VERSION ""

NS_ :

BS_:

BU_: Pegasus Marvel Laptop Stark Xavier stark NBMS Pegasus Marvel Laptop Stark Xavier stark Gtake

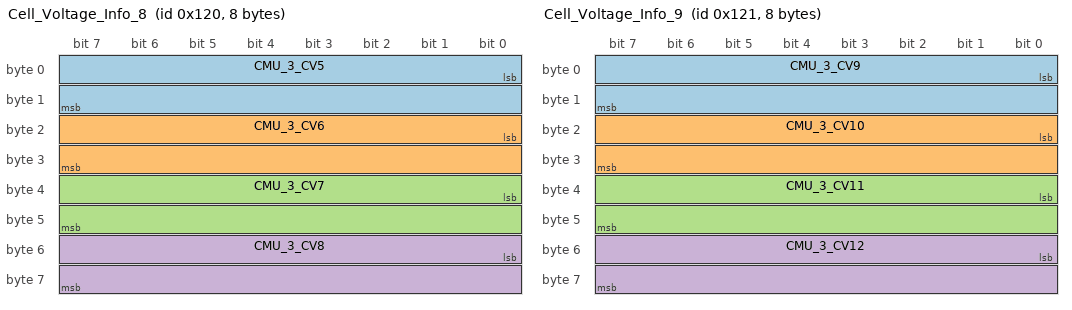
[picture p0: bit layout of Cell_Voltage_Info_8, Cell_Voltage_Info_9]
BO_ 288 Cell_Voltage_Info_8: 8 NBMS
 SG_ CMU_3_CV5 : 0|16@1+ (0.1,0) [0|6553.5] "mV" Vector__XXX
 SG_ CMU_3_CV6 : 16|16@1+ (0.1,0) [0|6553.5] "mV" Vector__XXX
 SG_ CMU_3_CV7 : 32|16@1+ (0.1,0) [0|6553.5] "mV" Vector__XXX
 SG_ CMU_3_CV8 : 48|16@1+ (0.1,0) [0|6553.5] "mV" Vector__XXX

BO_ 298 Battery_Parameters_4: 8 NBMS
 SG_ DCLI : 0|16@1+ (0.1,0) [0|6553.5] "A" Vector__XXX
 SG_ DCLO : 16|16@1+ (0.1,0) [0|6553.5] "A" Vector__XXX

BO_ 289 Cell_Voltage_Info_9: 8 NBMS
 SG_ CMU_3_CV9 : 0|16@1+ (0.1,0) [0|6553.5] "mV" Vector__XXX
 SG_ CMU_3_CV10 : 16|16@1+ (0.1,0) [0|6553.5] "mV" Vector__XXX
 SG_ CMU_3_CV11 : 32|16@1+ (0.1,0) [0|6553.5] "mV" Vector__XXX
 SG_ CMU_3_CV12 : 48|16@1+ (0.1,0) [0|6553.5] "mV" Vector__XXX

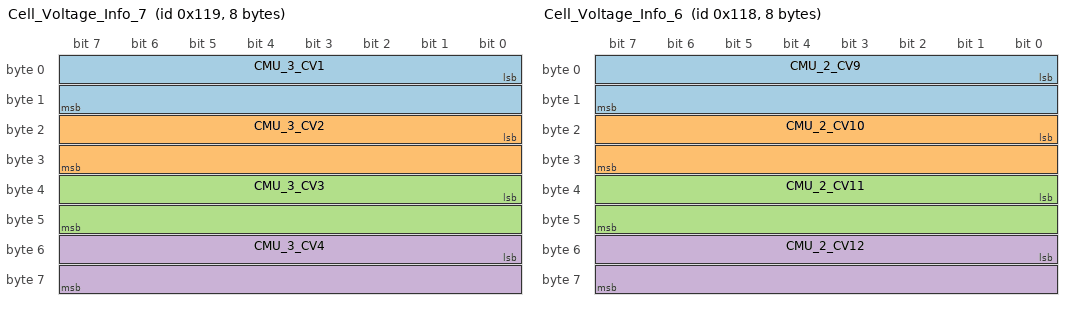
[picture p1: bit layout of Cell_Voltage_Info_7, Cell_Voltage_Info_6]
BO_ 281 Cell_Voltage_Info_7: 8 NBMS
 SG_ CMU_3_CV1 : 0|16@1+ (0.1,0) [0|6553.5] "mV" Vector__XXX
 SG_ CMU_3_CV2 : 16|16@1+ (0.1,0) [0|6553.5] "mV" Vector__XXX
 SG_ CMU_3_CV3 : 32|16@1+ (0.1,0) [0|6553.5] "mV" Vector__XXX
 SG_ CMU_3_CV4 : 48|16@1+ (0.1,0) [0|6553.5] "mV" Vector__XXX

BO_ 280 Cell_Voltage_Info_6: 8 NBMS
 SG_ CMU_2_CV9 : 0|16@1+ (0.1,0) [0|6553.5] "mV" Vector__XXX
 SG_ CMU_2_CV10 : 16|16@1+ (0.1,0) [0|6553.5] "mV" Vector__XXX
 SG_ CMU_2_CV11 : 32|16@1+ (0.1,0) [0|6553.5] "mV" Vector__XXX
 SG_ CMU_2_CV12 : 48|16@1+ (0.1,0) [0|6553.5] "mV" Vector__XXX

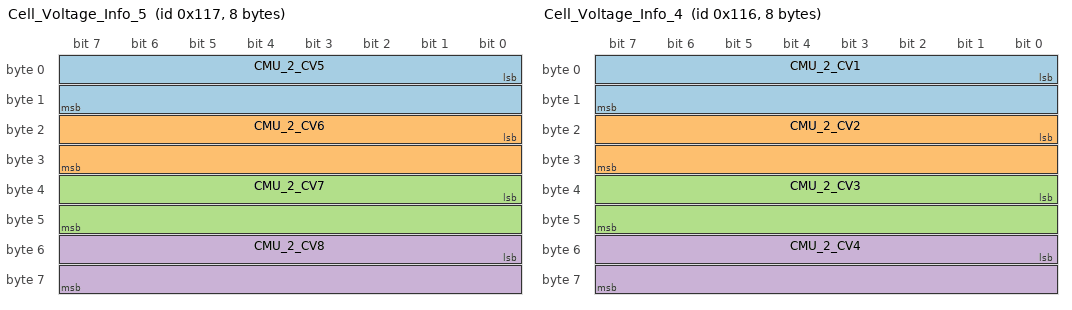
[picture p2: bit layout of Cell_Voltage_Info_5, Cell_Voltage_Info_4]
BO_ 279 Cell_Voltage_Info_5: 8 NBMS
 SG_ CMU_2_CV5 : 0|16@1+ (0.1,0) [0|6553.5] "mV" Vector__XXX
 SG_ CMU_2_CV6 : 16|16@1+ (0.1,0) [0|6553.5] "mV" Vector__XXX
 SG_ CMU_2_CV7 : 32|16@1+ (0.1,0) [0|6553.5] "mV" Vector__XXX
 SG_ CMU_2_CV8 : 48|16@1+ (0.1,0) [0|6553.5] "mV" Vector__XXX

BO_ 278 Cell_Voltage_Info_4: 8 NBMS
 SG_ CMU_2_CV1 : 0|16@1+ (0.1,0) [0|6553.5] "mV" Vector__XXX
 SG_ CMU_2_CV2 : 16|16@1+ (0.1,0) [0|6553.5] "mV" Vector__XXX
 SG_ CMU_2_CV3 : 32|16@1+ (0.1,0) [0|6553.5] "mV" Vector__XXX
 SG_ CMU_2_CV4 : 48|16@1+ (0.1,0) [0|6553.5] "mV" Vector__XXX

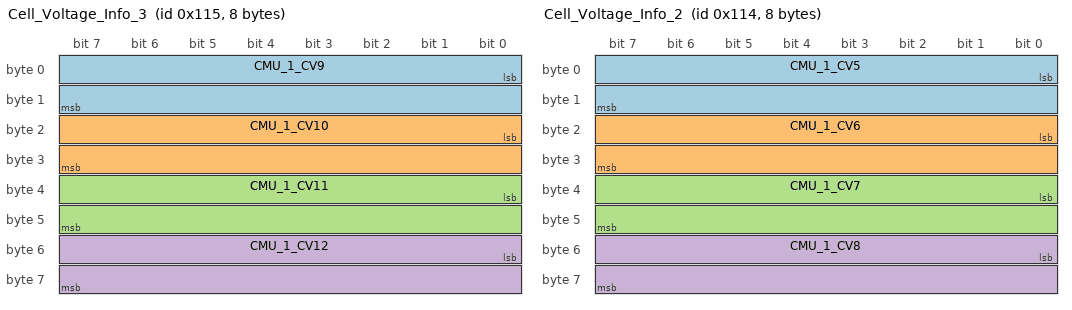
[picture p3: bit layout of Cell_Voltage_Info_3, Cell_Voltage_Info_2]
BO_ 277 Cell_Voltage_Info_3: 8 NBMS
 SG_ CMU_1_CV9 : 0|16@1+ (0.1,0) [0|6553.5] "mV" Vector__XXX
 SG_ CMU_1_CV10 : 16|16@1+ (0.1,0) [0|6553.5] "mV" Vector__XXX
 SG_ CMU_1_CV11 : 32|16@1+ (0.1,0) [0|6553.5] "mV" Vector__XXX
 SG_ CMU_1_CV12 : 48|16@1+ (0.1,0) [0|6553.5] "mV" Vector__XXX

BO_ 276 Cell_Voltage_Info_2: 8 NBMS
 SG_ CMU_1_CV5 : 0|16@1+ (0.1,0) [0|6553.5] "mV" Vector__XXX
 SG_ CMU_1_CV6 : 16|16@1+ (0.1,0) [0|6553.5] "mV" Vector__XXX
 SG_ CMU_1_CV7 : 32|16@1+ (0.1,0) [0|6553.5] "mV" Vector__XXX
 SG_ CMU_1_CV8 : 48|16@1+ (0.1,0) [0|6553.5] "mV" Vector__XXX

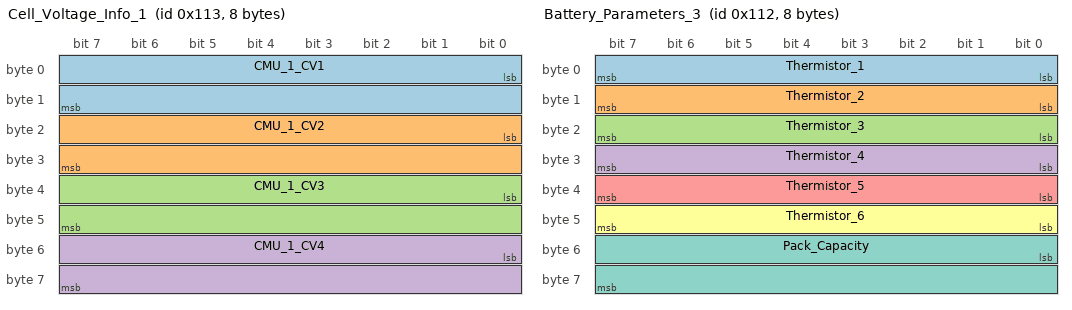
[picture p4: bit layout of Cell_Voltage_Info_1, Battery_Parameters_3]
BO_ 275 Cell_Voltage_Info_1: 8 NBMS
 SG_ CMU_1_CV1 : 0|16@1+ (0.1,0) [0|6553.5] "mV" Vector__XXX
 SG_ CMU_1_CV2 : 16|16@1+ (0.1,0) [0|6553.5] "mV" Vector__XXX
 SG_ CMU_1_CV3 : 32|16@1+ (0.1,0) [0|6553.5] "mV" Vector__XXX
 SG_ CMU_1_CV4 : 48|16@1+ (0.1,0) [0|6553.5] "mV" Vector__XXX

BO_ 274 Battery_Parameters_3: 8 NBMS
 SG_ Thermistor_1 : 0|8@1- (1,0) [-40|125] "C" Vector__XXX
 SG_ Thermistor_2 : 8|8@1- (1,0) [-40|125] "C" Vector__XXX
 SG_ Thermistor_3 : 16|8@1- (1,0) [-40|125] "C" Vector__XXX
 SG_ Thermistor_4 : 24|8@1- (1,0) [-40|125] "C" Vector__XXX
 SG_ Thermistor_5 : 32|8@1- (1,0) [-40|125] "C" Vector__XXX
 SG_ Thermistor_6 : 40|8@1- (1,0) [-40|125] "C" Vector__XXX
 SG_ Pack_Capacity : 48|16@1+ (0.1,0) [0|180] "Ah" Vector__XXX

BO_ 272 Battery_Parameters_2: 8 NBMS
 SG_ Pack_Current : 32|32@1- (1E-05,0) [21474.8|21474.8] "A" Vector__XXX
 SG_ Flag_PreCharge_Active : 16|8@1+ (1,0) [0|255] "" Vector__XXX

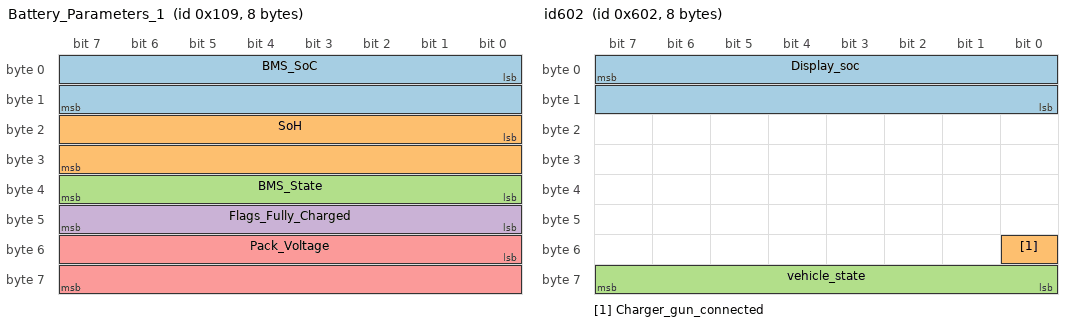
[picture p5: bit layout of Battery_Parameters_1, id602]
BO_ 265 Battery_Parameters_1: 8 NBMS
 SG_ BMS_SoC : 0|16@1+ (0.01,0) [0|655.35] "%" Vector__XXX
 SG_ SoH : 16|16@1+ (0.01,0) [0|655.35] "%" Vector__XXX
 SG_ BMS_State : 32|8@1+ (1,0) [0|255] "" Vector__XXX
 SG_ Flags_Fully_Charged : 40|8@1+ (1,0) [0|255] "" Vector__XXX
 SG_ Pack_Voltage : 48|16@1+ (0.1,0) [0|6553.5] "V" Vector__XXX

BO_ 600 Active_Error_BMS: 8 NBMS
 SG_ Active_error_Count : 40|16@1+ (1,0) [0|65535] "" Vector__XXX

BO_ 602 Error_Code_1_BMS: 8 NBMS
 SG_ Error_Code_1 : 55|16@0+ (1,0) [0|65535] "" Vector__XXX

BO_ 603 Error_Code_2_BMS: 8 NBMS
 SG_ Error_Code_2 : 55|16@0+ (1,0) [0|65535] "" Vector__XXX

BO_ 604 Error_Code_3_BMS: 8 NBMS
 SG_ Error_Code_3 : 55|16@0+ (1,0) [0|65535] "" Vector__XXX

BO_ 605 Error_Code_4_BMS: 8 NBMS
 SG_ Error_Code_4 : 55|16@0+ (1,0) [0|65535] "" Vector__XXX

BO_ 606 Error_Code_5_BMS: 8 NBMS
 SG_ Error_Code_5 : 55|16@0+ (1,0) [0|65535] "" Vector__XXX

BO_ 607 Error_Code_6_BMS: 8 NBMS
 SG_ Error_Code_6 : 55|16@0+ (1,0) [0|65535] "" Vector__XXX

BO_ 1538 id602: 8 Stark
 SG_ Display_soc : 7|16@0+ (0.1,0) [0|0] "%" Vector__XXX
 SG_ Charger_gun_connected : 48|1@1+ (1,0) [0|2] "" Vector__XXX
 SG_ vehicle_state : 63|8@0+ (1,0) [0|10] "" Vector__XXX

BO_ 1539 id603: 8 Stark
 SG_ Odometer : 23|32@0+ (0.01,0) [0|429496729.5] "Km" Vector__XXX

BO_ 1542 id606: 8 Stark
 SG_ Aux_battery_voltage : 15|16@0+ (0.01,0) [0|655.35] "V" Vector__XXX

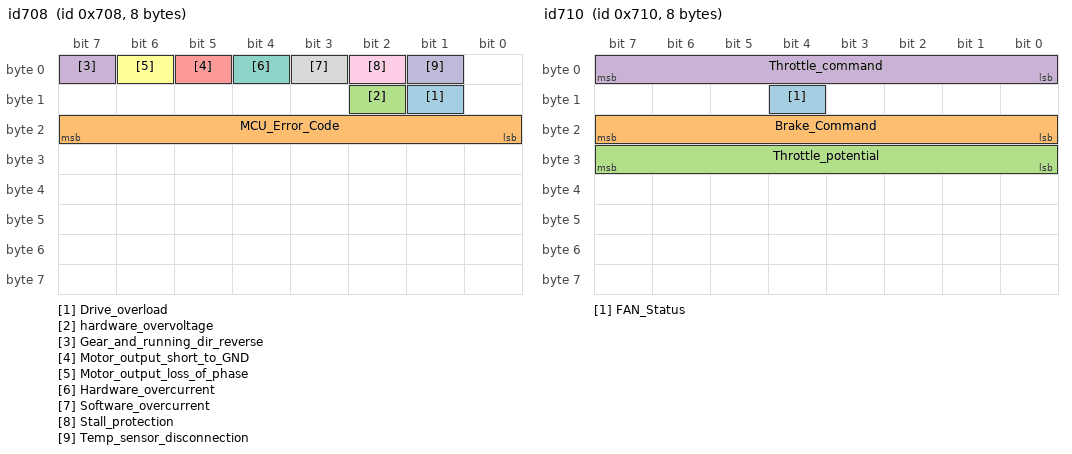
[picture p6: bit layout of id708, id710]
BO_ 1800 id708: 8 Gtake
 SG_ Drive_overload : 9|1@1+ (1,0) [0|1] "" Vector__XXX
 SG_ MCU_Error_Code : 16|8@1+ (1,0) [0|255] "" Vector__XXX
 SG_ hardware_overvoltage : 10|1@1+ (1,0) [0|1] "" Vector__XXX
 SG_ Gear_and_running_dir_reverse : 7|1@1+ (1,0) [0|1] "" Vector__XXX
 SG_ Motor_output_short_to_GND : 5|1@1+ (1,0) [0|1] "" Vector__XXX
 SG_ Motor_output_loss_of_phase : 6|1@1+ (1,0) [0|1] "" Vector__XXX
 SG_ Hardware_overcurrent : 4|1@1+ (1,0) [0|1] "" Vector__XXX
 SG_ Software_overcurrent : 3|1@1+ (1,0) [0|1] "" Vector__XXX
 SG_ Stall_protection : 2|1@1+ (1,0) [0|1] "" Vector__XXX
 SG_ Temp_sensor_disconnection : 1|1@1+ (1,0) [0|1] "" Vector__XXX

BO_ 1828 id724: 8 Gtake
 SG_ Motor_Torque_Estimated : 0|16@1- (0.1,0) [-3276.8|3276.7] "Nm" Vector__XXX

BO_ 1815 id717: 8 Gtake
 SG_ Operating_frequency : 0|16@1- (1,0) [-32768|32767] "Hz" Vector__XXX

BO_ 1814 id716: 8 Gtake
 SG_ VRMS : 40|8@1+ (1,0) [0|255] "V rms" Vector__XXX
 SG_ ARMS : 48|16@1+ (1,0) [0|65535] "A rms" Vector__XXX

BO_ 1808 id710: 8 Gtake
 SG_ FAN_Status : 12|1@1+ (1,0) [0|1] "" Vector__XXX
 SG_ Brake_Command : 16|8@1+ (1,0) [0|1] "" Vector__XXX
 SG_ Throttle_potential : 24|8@1+ (0.1,0) [0|25.5] "V" Vector__XXX
 SG_ Throttle_command : 0|8@1+ (1,0) [0|255] "%" Vector__XXX

BO_ 1813 id715: 8 Gtake
 SG_ Capacitor_Voltage : 32|8@1+ (1,0) [0|255] "V" Vector__XXX
 SG_ RPM : 48|16@1+ (1,0) [0|65535] "RPM" Vector__XXX

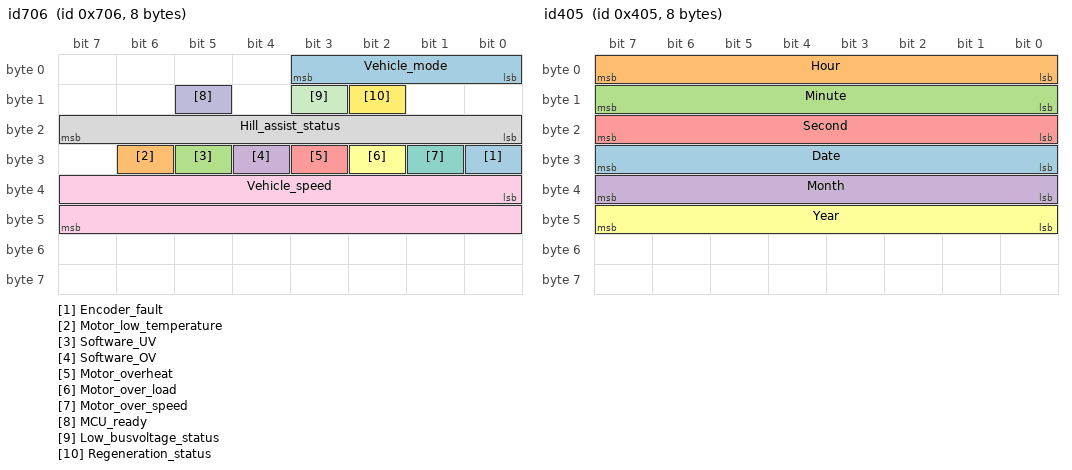
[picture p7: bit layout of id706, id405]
BO_ 1798 id706: 8 Gtake
 SG_ Encoder_fault : 24|1@1+ (1,0) [0|1] "" Vector__XXX
 SG_ Motor_low_temperature : 30|1@1+ (1,0) [0|1] "" Vector__XXX
 SG_ Software_UV : 29|1@1+ (1,0) [0|1] "" Vector__XXX
 SG_ Software_OV : 28|1@1+ (1,0) [0|1] "" Vector__XXX
 SG_ Motor_overheat : 27|1@1+ (1,0) [0|1] "" Vector__XXX
 SG_ Motor_over_load : 26|1@1+ (1,0) [0|1] "" Vector__XXX
 SG_ Motor_over_speed : 25|1@1+ (1,0) [0|0] "" Vector__XXX
 SG_ Hill_assist_status : 16|8@1+ (1,0) [0|255] "" Vector__XXX
 SG_ Vehicle_speed : 32|16@1- (0.1,0) [-3276.8|3276.7] "Kmph" Vector__XXX
 SG_ MCU_ready : 13|1@1+ (1,0) [0|1] "" Vector__XXX
 SG_ Low_busvoltage_status : 11|1@1+ (1,0) [0|0] "" Vector__XXX
 SG_ Regeneration_status : 10|1@1+ (1,0) [0|1] "" Vector__XXX
 SG_ Vehicle_mode : 0|4@1+ (1,0) [0|15] "" Vector__XXX

BO_ 1797 id705: 8 Gtake
 SG_ MCU_Temperature : 8|8@1+ (1,-50) [-50|205] "" Vector__XXX
 SG_ Motor_Temperature : 0|8@1+ (1,-50) [-50|205] "" Vector__XXX

BO_ 1025 id401: 8 Xavier
 SG_ Display_Speed : 0|8@1+ (1,0) [0|255] "Kmph" Vector__XXX

BO_ 1029 id405: 8 Xavier
 SG_ Date : 24|8@1+ (1,0) [0|0] "" Vector__XXX
 SG_ Hour : 0|8@1+ (1,0) [0|0] "" Vector__XXX
 SG_ Minute : 8|8@1+ (1,0) [0|0] "" Vector__XXX
 SG_ Month : 32|8@1+ (1,0) [0|0] "" Vector__XXX
 SG_ Second : 16|8@1+ (1,0) [0|0] "" Vector__XXX
 SG_ Year : 40|8@1+ (1,0) [0|0] "" Vector__XXX

BA_DEF_ SG_  "SigType" ENUM  "Default","Range","RangeSigned","ASCII","Discrete","Control","ReferencePGN","DTC","StringDelimiter","StringLength","StringLengthControl","MessageCounter","MessageChecksum";
BA_DEF_ SG_  "GenSigSendType" ENUM  "Cyclic","OnWrite","OnWriteWithRepetition","OnChange","OnChangeWithRepetition","IfActive","IfActiveWithRepetition","NoSigSendType";
BA_DEF_ SG_  "GenSigStartValue" INT 0 2147483647;
BA_DEF_ BO_  "GenMsgSendType" ENUM  "cyclic","NotUsed","IfActive","NotUsed","NotUsed","NotUsed","NotUsed","NotUsed","noMsgSendType";
BA_DEF_  "DBName" STRING ;
BA_DEF_ BO_  "VFrameFormat" ENUM  "StandardCAN","ExtendedCAN","reserved","J1939PG";
BA_DEF_ SG_  "SigType" ENUM  "Default","Range","RangeSigned","ASCII","Discrete","Control","ReferencePGN","DTC","StringDelimiter","StringLength","StringLengthControl","MessageCounter","MessageChecksum";
BA_DEF_ SG_  "GenSigSendType" ENUM  "Cyclic","OnWrite","OnWriteWithRepetition","OnChange","OnChangeWithRepetition","IfActive","IfActiveWithRepetition","NoSigSendType";
BA_DEF_ SG_  "GenSigStartValue" INT 0 2147483647;
BA_DEF_ BO_  "GenMsgSendType" ENUM  "cyclic","NotUsed","IfActive","NotUsed","NotUsed","NotUsed","NotUsed","NotUsed","noMsgSendType";
BA_DEF_  "DBName" STRING ;
BA_DEF_ BO_  "VFrameFormat" ENUM  "StandardCAN","ExtendedCAN","reserved","J1939PG";
BA_DEF_ SG_  "SigType" ENUM  "Default","Range","RangeSigned","ASCII","Discrete","Control","ReferencePGN","DTC","StringDelimiter","StringLength","StringLengthControl","MessageCounter","MessageChecksum";
BA_DEF_ SG_  "GenSigSendType" ENUM  "Cyclic","OnWrite","OnWriteWithRepetition","OnChange","OnChangeWithRepetition","IfActive","IfActiveWithRepetition","NoSigSendType";
BA_DEF_ SG_  "GenSigStartValue" INT 0 2147483647;
BA_DEF_ BO_  "GenMsgSendType" ENUM  "cyclic","NotUsed","IfActive","NotUsed","NotUsed","NotUsed","NotUsed","NotUsed","noMsgSendType";
BA_DEF_  "DBName" STRING ;
BA_DEF_ BO_  "VFrameFormat" ENUM  "StandardCAN","ExtendedCAN","reserved","J1939PG";
BA_DEF_DEF_  "SigType" "Default";
BA_DEF_DEF_  "GenSigSendType" "Cyclic";
BA_DEF_DEF_  "GenSigStartValue" 0;
BA_DEF_DEF_  "GenMsgSendType" "cyclic";
BA_DEF_DEF_  "DBName" "";
BA_DEF_DEF_  "VFrameFormat" "StandardCAN";
BA_DEF_DEF_  "SigType" "Default";
BA_DEF_DEF_  "GenSigSendType" "Cyclic";
BA_DEF_DEF_  "GenSigStartValue" 0;
BA_DEF_DEF_  "GenMsgSendType" "cyclic";
BA_DEF_DEF_  "DBName" "";
BA_DEF_DEF_  "VFrameFormat" "StandardCAN";
BA_DEF_DEF_  "SigType" "Default";
BA_DEF_DEF_  "GenSigSendType" "Cyclic";
BA_DEF_DEF_  "GenSigStartValue" 0;
BA_DEF_DEF_  "GenMsgSendType" "cyclic";
BA_DEF_DEF_  "DBName" "";
BA_DEF_DEF_  "VFrameFormat" "StandardCAN";
BA_ "DBName" "D03CAN";
BA_ "DBName" "D03CAN";
BA_ "DBName" "D03CAN";
BA_ "GenSigStartValue" SG_ 1797 MCU_Temperature 50;
BA_ "GenSigStartValue" SG_ 1797 Motor_Temperature 50;
VAL_ 1538 Charger_gun_connected 0 "0" 1 "1" ;
VAL_ 1538 vehicle_state 0 "0" 1 "1" 2 "2" 3 "3" ;
VAL_ 1800 Drive_overload 1 "1" 0 "0" ;
VAL_ 1800 hardware_overvoltage 0 "0" 1 "1" ;
VAL_ 1800 Gear_and_running_dir_reverse 1 "1" 0 "0" ;
VAL_ 1800 Motor_output_short_to_GND 1 "1" 0 "0" ;
VAL_ 1800 Motor_output_loss_of_phase 1 "1" 0 "0" ;
VAL_ 1800 Hardware_overcurrent 1 "1" 0 "0" ;
VAL_ 1800 Software_overcurrent 1 "1" 0 "0" ;
VAL_ 1800 Stall_protection 1 "1" 0 "0" ;
VAL_ 1800 Temp_sensor_disconnection 1 "1" 0 "0" ;
VAL_ 1808 FAN_Status 0 "0" 1 "1" ;
VAL_ 1808 Brake_Command 1 "1" 0 "0" ;
VAL_ 1798 Encoder_fault 1 "1" 0 "0" ;
VAL_ 1798 Motor_low_temperature 1 "1" 0 "0" ;
VAL_ 1798 Software_UV 1 "1" 0 "0" ;
VAL_ 1798 Software_OV 1 "1" 0 "0" ;
VAL_ 1798 Motor_overheat 1 "1" 0 "0" ;
VAL_ 1798 Motor_over_load 1 "1" 0 "0" ;
VAL_ 1798 Motor_over_speed 1 "1" 0 "0" ;
VAL_ 1798 MCU_ready 1 "1" 0 "0" ;
VAL_ 1798 Low_busvoltage_status 1 "1" 0 "0" ;
VAL_ 1798 Regeneration_status 1 "1" 0 "0" ;
VAL_ 1798 Vehicle_mode 8 "Thunder" 4 "Reverse" 2 "Eco" 1 "Neutral" ;
